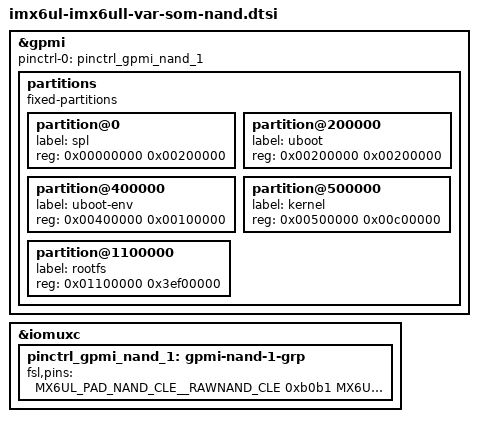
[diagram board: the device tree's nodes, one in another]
// SPDX-License-Identifier: GPL-2.0+
/*
 * Copyright (C) 2026 Variscite Ltd. - https://www.variscite.com
 */

&gpmi {
	pinctrl-names = "default";
	pinctrl-0 = <&pinctrl_gpmi_nand_1>;
	status = "okay";

	partitions {
		compatible = "fixed-partitions";
		#address-cells = <1>;
		#size-cells = <1>;

		partition@0 {
			label = "spl";
			reg = <0x00000000 0x00200000>;
		};

		partition@200000 {
			label = "uboot";
			reg = <0x00200000 0x00200000>;
		};

		partition@400000 {
			label = "uboot-env";
			reg = <0x00400000 0x00100000>;
		};

		partition@500000 {
			label = "kernel";
			reg = <0x00500000 0x00c00000>;
		};

		partition@1100000 {
			label = "rootfs";
			reg = <0x01100000 0x3ef00000>;
		};
	};
};

&iomuxc {
	pinctrl_gpmi_nand_1: gpmi-nand-1-grp {
		fsl,pins = <
			MX6UL_PAD_NAND_CLE__RAWNAND_CLE		0xb0b1
			MX6UL_PAD_NAND_ALE__RAWNAND_ALE		0xb0b1
			MX6UL_PAD_NAND_WP_B__RAWNAND_WP_B	0xb0b1
			MX6UL_PAD_NAND_READY_B__RAWNAND_READY_B	0xb000
			MX6UL_PAD_NAND_CE0_B__RAWNAND_CE0_B	0xb0b1
			MX6UL_PAD_NAND_RE_B__RAWNAND_RE_B	0xb0b1
			MX6UL_PAD_NAND_WE_B__RAWNAND_WE_B	0xb0b1
			MX6UL_PAD_NAND_DATA00__RAWNAND_DATA00	0xb0b1
			MX6UL_PAD_NAND_DATA01__RAWNAND_DATA01	0xb0b1
			MX6UL_PAD_NAND_DATA02__RAWNAND_DATA02	0xb0b1
			MX6UL_PAD_NAND_DATA03__RAWNAND_DATA03	0xb0b1
			MX6UL_PAD_NAND_DATA04__RAWNAND_DATA04	0xb0b1
			MX6UL_PAD_NAND_DATA05__RAWNAND_DATA05	0xb0b1
			MX6UL_PAD_NAND_DATA06__RAWNAND_DATA06	0xb0b1
			MX6UL_PAD_NAND_DATA07__RAWNAND_DATA07	0xb0b1
		>;
	};
};
